AUTOSAR XML (schema 4-3-0)
# \copyright BMW AG 2016 - 2017
package /BMW/Platform/IntegrationSample/SwComponentTypes
  swc implementation IMPL_IntegrationSample: programming-language=C, sw-version=5.0.3, vendor-id=5, behavior=IB_IntegrationSample
    code-descriptors:
      code Code1: artifact-descriptors=autosar-engineering-object={short-label=-, category=-}
    resource consumption ResConsumption1
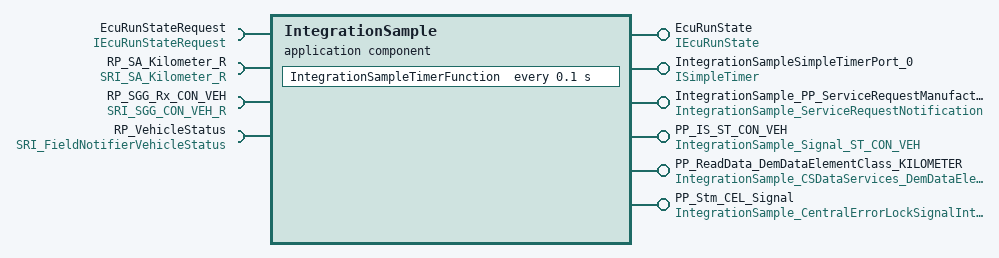
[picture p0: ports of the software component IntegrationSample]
  application sw component type IntegrationSample
    provide port EcuRunState: mode-switch-sender-com-spec{mode-group=EcuRunStateMode, queue-length=1}, provided-interface=IEcuRunState
    provide port IntegrationSampleSimpleTimerPort_0: mode-switch-sender-com-spec{mode-group=SimpleTimerMode, queue-length=2}, provided-interface=ISimpleTimer
    require port EcuRunStateRequest: nonqueued-receiver-com-spec{data-element=IntegrationSample_EcuRunStateRequestMode, uses-end-to-end-protection=FALSE, init-value=IntegrationSample_STARTUP}, required-interface=IEcuRunStateRequest
    4 x provide port:
      IntegrationSample_PP_ServiceRequestManufacturerNotificationPort: provided-interface=IntegrationSample_ServiceRequestNotification
      PP_IS_ST_CON_VEH: nonqueued-sender-com-spec{data-element=VehicleState, uses-end-to-end-protection=0, init-value=PP_IS_ST_CON_VEH_InvalidValue:15}, provided-interface=IntegrationSample_Signal_ST_CON_VEH
      PP_ReadData_DemDataElementClass_KILOMETER: server-com-spec{operation=ReadData, queue-length=1}, provided-interface=IntegrationSample_CSDataServices_DemDataElementClass_KILOMETER
      PP_Stm_CEL_Signal: provided-interface=IntegrationSample_CentralErrorLockSignalInterface
    require port RP_SA_Kilometer_R: nonqueued-receiver-com-spec{data-element=Notifier, alive-timeout=20.0, enable-update=true, init-value={short-label=value_CrBrLeft1Dot6777215E7CrBrRight, fields=value_1Dot6777215E7:16777215}}, required-interface=SRI_SA_Kilometer_R
    require port RP_SGG_Rx_CON_VEH: nonqueued-receiver-com-spec{data-element=IntegrationSample_IDT_CON_VEH, uses-end-to-end-protection=0, alive-timeout=0.5, enable-update=true, init-value={short-label=IntegrationSample_InitValues_SGG_Rx_CON_VEH, fields=[IV_SGG_Rx_CON_VEH_ST_CON_VEH:0xF, IV_SGG_Rx_CON_VEH_CTR_FKTN_PRTNT:0xFFFFFFFF, IV_SGG_Rx_CON_VEH_CTR_BS_PRTNT:0xF]}}, required-interface=SRI_SGG_CON_VEH_R
    require port RP_VehicleStatus: nonqueued-receiver-com-spec{data-element=Notifier, uses-end-to-end-protection=0, alive-timeout=21.0, enable-update=true, init-value=fields=[0, 0]}, required-interface=SRI_FieldNotifierVehicleStatus
    behavior IB_IntegrationSample: data-type-mapping=[IntegrationSampleModemappingEcuRunState, IntegrationSampleModemappingSimpleTimerMode], handle-termination-and-restart=NO-SUPPORT
      exclusive area EXA_IntegrationSample
      timing event IntegrationSample_SimpleTimer_TimingEvent: start-on-event=IntegrationSampleTimerFunction, period=0.1
      data received event DRE_SGG_Rx_CON_VEH: start-on-event=R_Receive_SGG_Rx_CON_VEH, data=RP_SGG_Rx_CON_VEH.IntegrationSample_IDT_CON_VEH
      data receive error event DRET_SGG_Rx_CON_VEH: start-on-event=R_Timeout_SGG_Rx_CON_VEH, data=RP_SGG_Rx_CON_VEH.IntegrationSample_IDT_CON_VEH
      data received event DRE_SIG_MILE_KM_816_R: start-on-event=R_Receive_SIG_MILE_KM_816_R, data=RP_SA_Kilometer_R.Notifier
      data received event EcuRunState: start-on-event=R_IntegrationSample_EcuRunStateHandler, data=EcuRunStateRequest.IntegrationSample_EcuRunStateRequestMode
      data received event DRE_VehicleStatus: start-on-event=R_Receive_VehicleStatus, data=RP_VehicleStatus.Notifier
      data receive error event DRET_VehicleStatus: start-on-event=R_Timeout_VehicleStatus, data=RP_VehicleStatus.Notifier
      operation invoked event IntegrationSample_Event_ManufacturerConfirmation: start-on-event=IntegrationSample_Runnable_ManufacturerConfirmation, operation=IntegrationSample_PP_ServiceRequestManufacturerNotificationPort.Confirmation
      operation invoked event IntegrationSample_Event_ManufacturerIndication: start-on-event=IntegrationSample_Runnable_ManufacturerIndication, operation=IntegrationSample_PP_ServiceRequestManufacturerNotificationPort.Indication
      operation invoked event OIE_ReadDataMILE_KM: start-on-event=R_ReadDataMILE_KM, operation=PP_ReadData_DemDataElementClass_KILOMETER.ReadData
      10 x runnable:
        IntegrationSample_Runnable_ManufacturerConfirmation: can-be-invoked-concurrently=true, symbol=IntegrationSample_ManufacturerConfirmation
        IntegrationSample_Runnable_ManufacturerIndication: can-be-invoked-concurrently=true, symbol=IntegrationSample_ManufacturerIndication
        R_IntegrationSample_EcuRunStateHandler: mode-access-point=EcuRunState.EcuRunStateMode, symbol=IntegrationSample_EcuRunStateHandler
          data-read-access:
            access DRA_requestMode: accessed-variable=EcuRunStateRequest.IntegrationSample_EcuRunStateRequestMode
          mode switch point MSP_Mode: mode-group=EcuRunState.EcuRunStateMode
        R_ReadDataMILE_KM: can-enter-exclusive-area=EXA_IntegrationSample, can-be-invoked-concurrently=true
        R_Receive_SGG_Rx_CON_VEH: can-enter-exclusive-area=EXA_IntegrationSample, can-be-invoked-concurrently=true
          data-receive-point-by-arguments:
            access IntegrationSample_DRP0_SGG_Rx_CON_VEH: accessed-variable={autosar-variable=RP_SGG_Rx_CON_VEH.IntegrationSample_IDT_CON_VEH, local-variable=IntegrationSample_IDT_CON_VEH}
          data-send-points:
            access VariableAccess_ST_CON_VEH: accessed-variable=PP_IS_ST_CON_VEH.VehicleState.VehicleState, scope=COMMUNICATION-INTER-ECU
        R_Timeout_SGG_Rx_CON_VEH: can-be-invoked-concurrently=true, symbol=Runnable_IS_R_Timeout_SGG_Rx_CON_VEH
        R_Receive_SIG_MILE_KM_816_R: can-enter-exclusive-area=EXA_IntegrationSample, can-be-invoked-concurrently=true, symbol=Runnable_IS_Receive_SIG_MILE_KM_816_R
          data-receive-point-by-arguments:
            access IntegrationSample_VariableAccess_SIG_MILE_KM_816_R: accessed-variable={autosar-variable=RP_SA_Kilometer_R.Notifier, local-variable=Notifier}
        IntegrationSampleTimerFunction: symbol=R_IntegrationSample_TimerFunction
          mode switch point MSP_SampleTimer_Mode_0: mode-group=IntegrationSampleSimpleTimerPort_0.SimpleTimerMode
        R_Receive_VehicleStatus: can-enter-exclusive-area=EXA_IntegrationSample, can-be-invoked-concurrently=true, symbol=Runnable_IS_R_Receive_VehicleStatus
          data-receive-point-by-arguments:
            access IntegrationSample_VariableAccess_VehicleStatus: accessed-variable={autosar-variable=RP_VehicleStatus.Notifier, local-variable=Notifier}
          data-send-points:
            access VariableAccess_centralErrorLock: accessed-variable=PP_Stm_CEL_Signal.centralErrorLock.centralErrorLock
        R_Timeout_VehicleStatus: can-be-invoked-concurrently=true, symbol=Runnable_IS_R_Timeout_VehicleStatus
